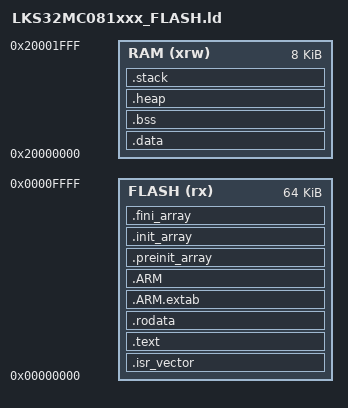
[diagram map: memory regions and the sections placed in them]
ENTRY(Reset_Handler)

_estack = 0x20002000;    /* ջ����8KB RAMĩ�ˣ� */

MEMORY {
  FLASH (rx) : ORIGIN = 0x00000000, LENGTH = 64K
  RAM (xrw)  : ORIGIN = 0x20000000, LENGTH = 8K
}

SECTIONS {
  .isr_vector : {
    . = ALIGN(4);
    KEEP(*(.isr_vector))
    . = ALIGN(4);
  } >FLASH

  .text : {
    . = ALIGN(4);
    *(.text)
    *(.text*)
    *(.glue_7t)
    *(.eh_frame)
    KEEP (*(.init))
    KEEP (*(.fini))
    . = ALIGN(4);
    _etext = .;
  } >FLASH

  .rodata : {
    . = ALIGN(4);
    *(.rodata)
    *(.rodata*)
    . = ALIGN(4);
  } >FLASH

  .ARM.extab : { *(.ARM.extab*) } >FLASH
  .ARM : {
    __exidx_start = .;
    *(.ARM.exidx*)
    __exidx_end = .;
  } >FLASH

  .preinit_array : {
    PROVIDE_HIDDEN (__preinit_array_start = .);
    KEEP (*(.preinit_array*))
    PROVIDE_HIDDEN (__preinit_array_end = .);
  } >FLASH

  .init_array : {
    PROVIDE_HIDDEN (__init_array_start = .);
    KEEP (*(SORT(.init_array.*)))
    KEEP (*(.init_array*))
    PROVIDE_HIDDEN (__init_array_end = .);
  } >FLASH

  .fini_array : {
    PROVIDE_HIDDEN (__fini_array_start = .);
    KEEP (*(SORT(.fini_array.*)))
    KEEP (*(.fini_array*))
    PROVIDE_HIDDEN (__fini_array_end = .);
  } >FLASH

  _sidata = .;
  .data : AT(_sidata) {
    . = ALIGN(4);
    _sdata = .;
    *(.data)
    *(.data*)
    . = ALIGN(4);
    _edata = .;
  } >RAM

  .bss : {
    . = ALIGN(4);
    _sbss = .;
    __bss_start__ = _sbss;
    *(.bss)
    *(.bss*)
    *(COMMON)
    . = ALIGN(4);
    _ebss = .;
    __bss_end__ = _ebss;
  } >RAM

  .heap (NOLOAD) : {
    . = ALIGN(8);
    __heap_base = .;
    . = . + 0x400;        /* 1KB�� */
    __heap_limit = .;
  } >RAM

  .stack (NOLOAD) : {
    . = ALIGN(8);
    . = . + 0x600;        /* 1.5KBջ */
    . = ALIGN(8);
    __initial_sp = .;
  } >RAM

  /DISCARD/ : {
    libc.a (*)
    libm.a (*)
    libgcc.a (*)
  }

  .ARM.attributes 0 : { *(.ARM.attributes) }
}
